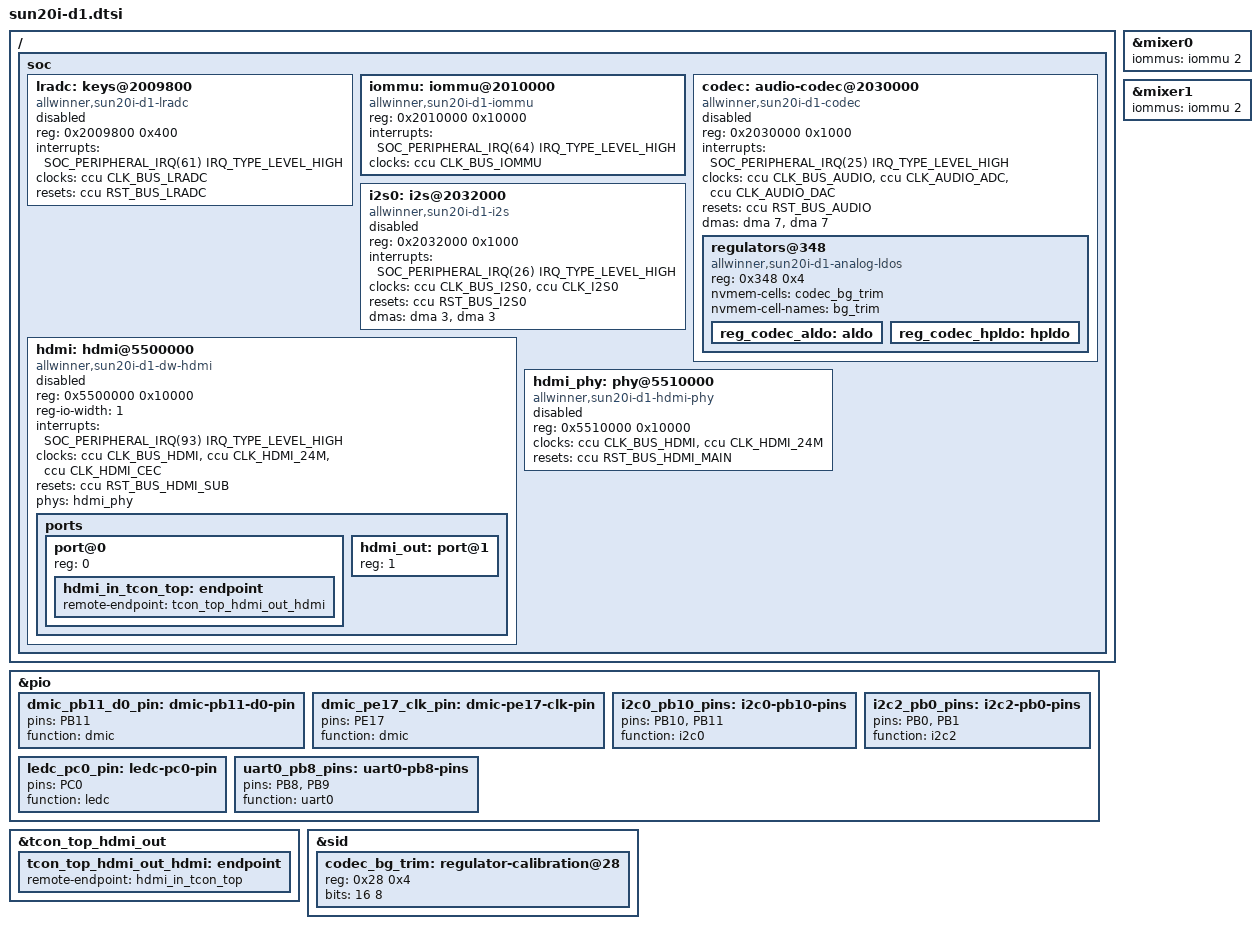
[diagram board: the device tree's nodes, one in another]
// SPDX-License-Identifier: (GPL-2.0+ OR MIT)
// Copyright (C) 2021-2022 Samuel Holland <samuel@sholland.org>

#include "sun20i-d1s.dtsi"
#include "sunxi-d1-t113.dtsi"

/ {
	soc {
		lradc: keys@2009800 {
			compatible = "allwinner,sun20i-d1-lradc",
				     "allwinner,sun50i-r329-lradc";
			reg = <0x2009800 0x400>;
			interrupts = <SOC_PERIPHERAL_IRQ(61) IRQ_TYPE_LEVEL_HIGH>;
			clocks = <&ccu CLK_BUS_LRADC>;
			resets = <&ccu RST_BUS_LRADC>;
			status = "disabled";
		};

		iommu: iommu@2010000 {
			compatible = "allwinner,sun20i-d1-iommu";
			reg = <0x2010000 0x10000>;
			interrupts = <SOC_PERIPHERAL_IRQ(64) IRQ_TYPE_LEVEL_HIGH>;
			clocks = <&ccu CLK_BUS_IOMMU>;
			#iommu-cells = <1>;
		};

		codec: audio-codec@2030000 {
			compatible = "allwinner,sun20i-d1-codec", "simple-mfd", "syscon";
			reg = <0x2030000 0x1000>;
			interrupts = <SOC_PERIPHERAL_IRQ(25) IRQ_TYPE_LEVEL_HIGH>;
			clocks = <&ccu CLK_BUS_AUDIO>, <&ccu CLK_AUDIO_ADC>,
				 <&ccu CLK_AUDIO_DAC>;
			clock-names = "bus", "adc", "dac";
			resets = <&ccu RST_BUS_AUDIO>;
			dmas = <&dma 7>, <&dma 7>;
			dma-names = "rx", "tx";
			#address-cells = <1>;
			#size-cells = <1>;
			#sound-dai-cells = <0>;
			ranges = <0 0x2030000 0x1000>;
			status = "disabled";

			regulators@348 {
				compatible = "allwinner,sun20i-d1-analog-ldos";
				reg = <0x348 0x4>;
				nvmem-cells = <&codec_bg_trim>;
				nvmem-cell-names = "bg_trim";

				reg_codec_aldo: aldo {
				};

				reg_codec_hpldo: hpldo {
				};
			};
		};

		i2s0: i2s@2032000 {
			compatible = "allwinner,sun20i-d1-i2s",
				     "allwinner,sun50i-r329-i2s";
			reg = <0x2032000 0x1000>;
			interrupts = <SOC_PERIPHERAL_IRQ(26) IRQ_TYPE_LEVEL_HIGH>;
			clocks = <&ccu CLK_BUS_I2S0>,
				 <&ccu CLK_I2S0>;
			clock-names = "apb", "mod";
			resets = <&ccu RST_BUS_I2S0>;
			dmas = <&dma 3>, <&dma 3>;
			dma-names = "rx", "tx";
			status = "disabled";
			#sound-dai-cells = <0>;
		};

		hdmi: hdmi@5500000 {
			compatible = "allwinner,sun20i-d1-dw-hdmi";
			reg = <0x5500000 0x10000>;
			reg-io-width = <1>;
			interrupts = <SOC_PERIPHERAL_IRQ(93) IRQ_TYPE_LEVEL_HIGH>;
			clocks = <&ccu CLK_BUS_HDMI>, <&ccu CLK_HDMI_24M>,
				 <&ccu CLK_HDMI_CEC>;
			clock-names = "iahb", "isfr", "cec";
			resets = <&ccu RST_BUS_HDMI_SUB>;
			reset-names = "ctrl";
			phys = <&hdmi_phy>;
			phy-names = "phy";
			status = "disabled";

			ports {
				#address-cells = <1>;
				#size-cells = <0>;

				port@0 {
					reg = <0>;

					hdmi_in_tcon_top: endpoint {
						remote-endpoint = <&tcon_top_hdmi_out_hdmi>;
					};
				};

				hdmi_out: port@1 {
					reg = <1>;
				};
			};
		};

		hdmi_phy: phy@5510000 {
			compatible = "allwinner,sun20i-d1-hdmi-phy";
			reg = <0x5510000 0x10000>;
			clocks = <&ccu CLK_BUS_HDMI>, <&ccu CLK_HDMI_24M>;
			clock-names = "bus", "mod";
			resets = <&ccu RST_BUS_HDMI_MAIN>;
			reset-names = "phy";
			status = "disabled";
			#phy-cells = <0>;
		};
	};
};

&pio {
	/omit-if-no-ref/
	dmic_pb11_d0_pin: dmic-pb11-d0-pin {
		pins = "PB11";
		function = "dmic";
	};

	/omit-if-no-ref/
	dmic_pe17_clk_pin: dmic-pe17-clk-pin {
		pins = "PE17";
		function = "dmic";
	};

	/omit-if-no-ref/
	i2c0_pb10_pins: i2c0-pb10-pins {
		pins = "PB10", "PB11";
		function = "i2c0";
	};

	/omit-if-no-ref/
	i2c2_pb0_pins: i2c2-pb0-pins {
		pins = "PB0", "PB1";
		function = "i2c2";
	};

	/omit-if-no-ref/
	ledc_pc0_pin: ledc-pc0-pin {
		pins = "PC0";
		function = "ledc";
	};

	/omit-if-no-ref/
	uart0_pb8_pins: uart0-pb8-pins {
		pins = "PB8", "PB9";
		function = "uart0";
	};
};

&mixer0 {
	iommus = <&iommu 2>;
};

&mixer1 {
	iommus = <&iommu 2>;
};

&tcon_top_hdmi_out {
	tcon_top_hdmi_out_hdmi: endpoint {
		remote-endpoint = <&hdmi_in_tcon_top>;
	};
};

&sid {
	codec_bg_trim: regulator-calibration@28 {
		reg = <0x28 0x4>;
		bits = <16 8>;
	};
};
